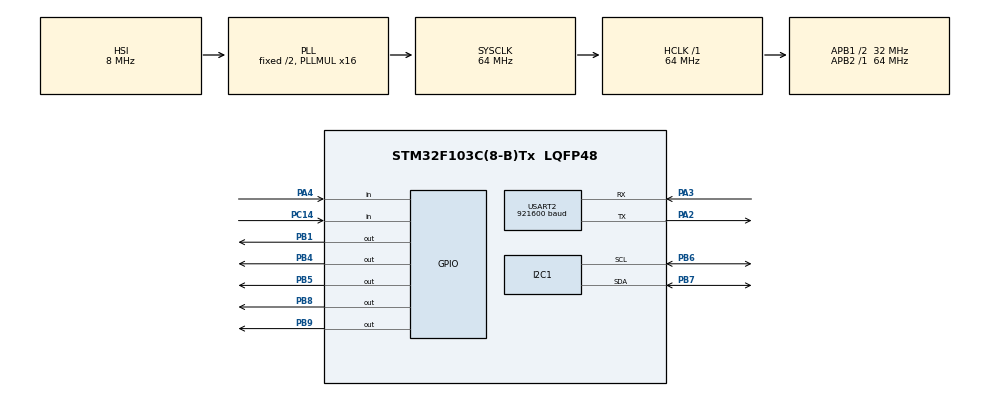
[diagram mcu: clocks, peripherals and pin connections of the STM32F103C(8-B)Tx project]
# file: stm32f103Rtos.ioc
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ADC1.Channel-0\#ChannelRegularConversion=ADC_CHANNEL_TEMPSENSOR
ADC1.NbrOfConversionFlag=1
ADC1.Rank-0\#ChannelRegularConversion=1
ADC1.SamplingTime-0\#ChannelRegularConversion=ADC_SAMPLETIME_1CYCLE_5
ADC1.master=1
Dma.Request0=USART2_RX
Dma.Request1=USART2_TX
Dma.USART2_RX.0.Direction=DMA_PERIPH_TO_MEMORY
Dma.USART2_RX.0.Instance=DMA1_Channel6
Dma.USART2_RX.0.MemDataAlignment=DMA_MDATAALIGN_BYTE
Dma.USART2_RX.0.MemInc=DMA_MINC_ENABLE
Dma.USART2_RX.0.Mode=DMA_NORMAL
Dma.USART2_RX.0.PeriphDataAlignment=DMA_PDATAALIGN_BYTE
Dma.USART2_RX.0.PeriphInc=DMA_PINC_DISABLE
Dma.USART2_RX.0.Priority=DMA_PRIORITY_LOW
Dma.USART2_TX.1.Direction=DMA_MEMORY_TO_PERIPH
Dma.USART2_TX.1.Instance=DMA1_Channel7
Dma.USART2_TX.1.MemDataAlignment=DMA_MDATAALIGN_BYTE
Dma.USART2_TX.1.MemInc=DMA_MINC_ENABLE
Dma.USART2_TX.1.Mode=DMA_NORMAL
Dma.USART2_TX.1.PeriphDataAlignment=DMA_PDATAALIGN_BYTE
Dma.USART2_TX.1.PeriphInc=DMA_PINC_DISABLE
Dma.USART2_TX.1.Priority=DMA_PRIORITY_LOW
FREERTOS.INCLUDE_uxTaskGetStackHighWaterMark=1
FREERTOS.Tasks01=defaultTask,-3,128,StartDefaultTask,Default,NULL,Dynamic,NULL,NULL
FREERTOS.configUSE_NEWLIB_REENTRANT=1
IWDG.Prescaler=IWDG_PRESCALER_64
Mcu.Family=STM32F1
Mcu.Name=STM32F103C(8-B)Tx
Mcu.Package=LQFP48
NVIC.DMA1_Channel6_IRQn=true\:6\:0\:true\:false\:true\:true\:true\:true
NVIC.DMA1_Channel7_IRQn=true\:6\:0\:true\:false\:true\:true\:true\:true
NVIC.I2C1_ER_IRQn=true\:5\:0\:false\:false\:true\:false\:true\:true
NVIC.I2C1_EV_IRQn=true\:5\:0\:false\:false\:true\:false\:true\:true
NVIC.PriorityGroup=NVIC_PRIORITYGROUP_4
NVIC.USART2_IRQn=true\:6\:0\:true\:false\:true\:true\:true\:true
PA13.Mode=Serial_Wire
PA13.Signal=SYS_JTMS-SWDIO
PA14.Mode=Serial_Wire
PA14.Signal=SYS_JTCK-SWCLK
PA2.Mode=Asynchronous
PA2.Signal=USART2_TX
PA3.Mode=Asynchronous
PA3.Signal=USART2_RX
PA4.Signal=GPIO_Input
PB1.Signal=GPIO_Output
PB4.Signal=GPIO_Output
PB5.Signal=GPIO_Output
PB6.Mode=I2C
PB6.Signal=I2C1_SCL
PB7.Mode=I2C
PB7.Signal=I2C1_SDA
PB8.Signal=GPIO_Output
PB9.Signal=GPIO_Output
PC14-OSC32_IN.Signal=GPIO_Input
ProjectManager.HeapSize=0x200
ProjectManager.StackSize=0x400
ProjectManager.TargetToolchain=STM32CubeIDE
RCC.ADCPresc=RCC_ADCPCLK2_DIV8
RCC.AHBFreq_Value=64000000
RCC.APB1CLKDivider=RCC_HCLK_DIV2
RCC.APB1Freq_Value=32000000
RCC.APB1TimFreq_Value=64000000
RCC.APB2Freq_Value=64000000
RCC.APB2TimFreq_Value=64000000
RCC.HCLKFreq_Value=64000000
RCC.PLLMUL=RCC_PLL_MUL16
RCC.SYSCLKFreq_VALUE=64000000
RCC.SYSCLKSource=RCC_SYSCLKSOURCE_PLLCLK
RCC.USBFreq_Value=64000000
USART2.BaudRate=921600
USART2.VirtualMode=VM_ASYNC
VP_ADC1_TempSens_Input.Mode=IN-TempSens
VP_CRC_VS_CRC.Mode=CRC_Activate
VP_FREERTOS_VS_CMSIS_V1.Mode=CMSIS_V1
VP_IWDG_VS_IWDG.Mode=IWDG_Activate
VP_TIM2_VS_ClockSourceINT.Mode=Internal
VP_TIM2_VS_ClockSourceITR.Mode=TriggerSource_ITR0
board=custom

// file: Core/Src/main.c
/* USER CODE BEGIN Header */
/**
  ******************************************************************************
  * @file           : main.c
  * @brief          : Main program body
  ******************************************************************************
  * @attention
  *
  * <h2><center>&copy; Copyright (c) 2021 STMicroelectronics.
  * All rights reserved.</center></h2>
  *
  * This software component is licensed by ST under Ultimate Liberty license
  * SLA0044, the "License"; You may not use this file except in compliance with
  * the License. You may obtain a copy of the License at:
  *                             www.st.com/SLA0044
  *
  ******************************************************************************
  */
/* USER CODE END Header */
#include "main.h"
#include "cmsis_os.h"

ADC_HandleTypeDef hadc1;

CRC_HandleTypeDef hcrc;

I2C_HandleTypeDef hi2c1;

IWDG_HandleTypeDef hiwdg;

TIM_HandleTypeDef htim2;

UART_HandleTypeDef huart2;
DMA_HandleTypeDef hdma_usart2_rx;
DMA_HandleTypeDef hdma_usart2_tx;

osThreadId defaultTaskHandle;

void SystemClock_Config(void);
static void MX_GPIO_Init(void);
static void MX_I2C1_Init(void);
static void MX_ADC1_Init(void);
static void MX_DMA_Init(void);
static void MX_USART2_UART_Init(void);
static void MX_TIM2_Init(void);
static void MX_IWDG_Init(void);
static void MX_CRC_Init(void);
void StartDefaultTask(void const * argument);

/* USER CODE BEGIN PFP */
extern void app_main();
/* USER CODE END PFP */

int main(void)
{

  /* MCU Configuration--------------------------------------------------------*/

  /* Reset of all peripherals, Initializes the Flash interface and the Systick. */
  HAL_Init();

  /* Configure the system clock */
  SystemClock_Config();

  /* Initialize all configured peripherals */
  MX_GPIO_Init();
  MX_I2C1_Init();
  MX_ADC1_Init();
  MX_DMA_Init();
  MX_USART2_UART_Init();
  MX_TIM2_Init();
  MX_IWDG_Init();
  MX_CRC_Init();

  /* Create the thread(s) */
  /* definition and creation of defaultTask */
  osThreadDef(defaultTask, StartDefaultTask, osPriorityIdle, 0, 128);
  defaultTaskHandle = osThreadCreate(osThread(defaultTask), NULL);

  /* USER CODE BEGIN RTOS_THREADS */
  /* add threads, ... */
  app_main();
  /* USER CODE END RTOS_THREADS */

  /* Start scheduler */
  osKernelStart();

  /* We should never get here as control is now taken by the scheduler */
  /* Infinite loop */
  while (1)
  {

  }
}

void SystemClock_Config(void)
{
  RCC_OscInitTypeDef RCC_OscInitStruct = {0};
  RCC_ClkInitTypeDef RCC_ClkInitStruct = {0};
  RCC_PeriphCLKInitTypeDef PeriphClkInit = {0};

  /** Initializes the RCC Oscillators according to the specified parameters
  * in the RCC_OscInitTypeDef structure.
  */
  RCC_OscInitStruct.OscillatorType = RCC_OSCILLATORTYPE_HSI|RCC_OSCILLATORTYPE_LSI;
  RCC_OscInitStruct.HSIState = RCC_HSI_ON;
  RCC_OscInitStruct.HSICalibrationValue = RCC_HSICALIBRATION_DEFAULT;
  RCC_OscInitStruct.LSIState = RCC_LSI_ON;
  RCC_OscInitStruct.PLL.PLLState = RCC_PLL_ON;
  RCC_OscInitStruct.PLL.PLLSource = RCC_PLLSOURCE_HSI_DIV2;
  RCC_OscInitStruct.PLL.PLLMUL = RCC_PLL_MUL16;
  if (HAL_RCC_OscConfig(&RCC_OscInitStruct) != HAL_OK)
  {
    Error_Handler();
  }
  /** Initializes the CPU, AHB and APB buses clocks
  */
  RCC_ClkInitStruct.ClockType = RCC_CLOCKTYPE_HCLK|RCC_CLOCKTYPE_SYSCLK
                              |RCC_CLOCKTYPE_PCLK1|RCC_CLOCKTYPE_PCLK2;
  RCC_ClkInitStruct.SYSCLKSource = RCC_SYSCLKSOURCE_PLLCLK;
  RCC_ClkInitStruct.AHBCLKDivider = RCC_SYSCLK_DIV1;
  RCC_ClkInitStruct.APB1CLKDivider = RCC_HCLK_DIV2;
  RCC_ClkInitStruct.APB2CLKDivider = RCC_HCLK_DIV1;

  if (HAL_RCC_ClockConfig(&RCC_ClkInitStruct, FLASH_LATENCY_2) != HAL_OK)
  {
    Error_Handler();
  }
  PeriphClkInit.PeriphClockSelection = RCC_PERIPHCLK_ADC;
  PeriphClkInit.AdcClockSelection = RCC_ADCPCLK2_DIV8;
  if (HAL_RCCEx_PeriphCLKConfig(&PeriphClkInit) != HAL_OK)
  {
    Error_Handler();
  }
}

static void MX_ADC1_Init(void)
{

  ADC_ChannelConfTypeDef sConfig = {0};

  /** Common config
  */
  hadc1.Instance = ADC1;
  hadc1.Init.ScanConvMode = ADC_SCAN_DISABLE;
  hadc1.Init.ContinuousConvMode = DISABLE;
  hadc1.Init.DiscontinuousConvMode = DISABLE;
  hadc1.Init.ExternalTrigConv = ADC_SOFTWARE_START;
  hadc1.Init.DataAlign = ADC_DATAALIGN_RIGHT;
  hadc1.Init.NbrOfConversion = 1;
  if (HAL_ADC_Init(&hadc1) != HAL_OK)
  {
    Error_Handler();
  }
  /** Configure Regular Channel
  */
  sConfig.Channel = ADC_CHANNEL_TEMPSENSOR;
  sConfig.Rank = ADC_REGULAR_RANK_1;
  sConfig.SamplingTime = ADC_SAMPLETIME_1CYCLE_5;
  if (HAL_ADC_ConfigChannel(&hadc1, &sConfig) != HAL_OK)
  {
    Error_Handler();
  }

}

static void MX_CRC_Init(void)
{

  /* USER CODE BEGIN CRC_Init 0 */
    __CRC_CLK_ENABLE();

  /* USER CODE END CRC_Init 0 */

  hcrc.Instance = CRC;
  if (HAL_CRC_Init(&hcrc) != HAL_OK)
  {
    Error_Handler();
  }

}

static void MX_I2C1_Init(void)
{

  hi2c1.Instance = I2C1;
  hi2c1.Init.ClockSpeed = 100000;
  hi2c1.Init.DutyCycle = I2C_DUTYCYCLE_2;
  hi2c1.Init.OwnAddress1 = 0;
  hi2c1.Init.AddressingMode = I2C_ADDRESSINGMODE_7BIT;
  hi2c1.Init.DualAddressMode = I2C_DUALADDRESS_DISABLE;
  hi2c1.Init.OwnAddress2 = 0;
  hi2c1.Init.GeneralCallMode = I2C_GENERALCALL_DISABLE;
  hi2c1.Init.NoStretchMode = I2C_NOSTRETCH_DISABLE;
  if (HAL_I2C_Init(&hi2c1) != HAL_OK)
  {
    Error_Handler();
  }

}

static void MX_IWDG_Init(void)
{

  hiwdg.Instance = IWDG;
  hiwdg.Init.Prescaler = IWDG_PRESCALER_64;
  hiwdg.Init.Reload = 4095;
  if (HAL_IWDG_Init(&hiwdg) != HAL_OK)
  {
    Error_Handler();
  }

}

static void MX_TIM2_Init(void)
{

  TIM_ClockConfigTypeDef sClockSourceConfig = {0};
  TIM_SlaveConfigTypeDef sSlaveConfig = {0};
  TIM_MasterConfigTypeDef sMasterConfig = {0};

  htim2.Instance = TIM2;
  htim2.Init.Prescaler = 0;
  htim2.Init.CounterMode = TIM_COUNTERMODE_UP;
  htim2.Init.Period = 65535;
  htim2.Init.ClockDivision = TIM_CLOCKDIVISION_DIV1;
  htim2.Init.AutoReloadPreload = TIM_AUTORELOAD_PRELOAD_DISABLE;
  if (HAL_TIM_Base_Init(&htim2) != HAL_OK)
  {
    Error_Handler();
  }
  sClockSourceConfig.ClockSource = TIM_CLOCKSOURCE_INTERNAL;
  if (HAL_TIM_ConfigClockSource(&htim2, &sClockSourceConfig) != HAL_OK)
  {
    Error_Handler();
  }
  sSlaveConfig.SlaveMode = TIM_SLAVEMODE_DISABLE;
  sSlaveConfig.InputTrigger = TIM_TS_ITR0;
  if (HAL_TIM_SlaveConfigSynchro(&htim2, &sSlaveConfig) != HAL_OK)
  {
    Error_Handler();
  }
  sMasterConfig.MasterOutputTrigger = TIM_TRGO_RESET;
  sMasterConfig.MasterSlaveMode = TIM_MASTERSLAVEMODE_DISABLE;
  if (HAL_TIMEx_MasterConfigSynchronization(&htim2, &sMasterConfig) != HAL_OK)
  {
    Error_Handler();
  }

}

static void MX_USART2_UART_Init(void)
{

  huart2.Instance = USART2;
  huart2.Init.BaudRate = 921600;
  huart2.Init.WordLength = UART_WORDLENGTH_8B;
  huart2.Init.StopBits = UART_STOPBITS_1;
  huart2.Init.Parity = UART_PARITY_NONE;
  huart2.Init.Mode = UART_MODE_TX_RX;
  huart2.Init.HwFlowCtl = UART_HWCONTROL_NONE;
  huart2.Init.OverSampling = UART_OVERSAMPLING_16;
  if (HAL_UART_Init(&huart2) != HAL_OK)
  {
    Error_Handler();
  }

}

static void MX_DMA_Init(void)
{

  /* DMA controller clock enable */
  __HAL_RCC_DMA1_CLK_ENABLE();

  /* DMA interrupt init */
  /* DMA1_Channel6_IRQn interrupt configuration */
  HAL_NVIC_SetPriority(DMA1_Channel6_IRQn, 6, 0);
  HAL_NVIC_EnableIRQ(DMA1_Channel6_IRQn);
  /* DMA1_Channel7_IRQn interrupt configuration */
  HAL_NVIC_SetPriority(DMA1_Channel7_IRQn, 6, 0);
  HAL_NVIC_EnableIRQ(DMA1_Channel7_IRQn);

}

static void MX_GPIO_Init(void)
{
  GPIO_InitTypeDef GPIO_InitStruct = {0};

  /* GPIO Ports Clock Enable */
  __HAL_RCC_GPIOC_CLK_ENABLE();
  __HAL_RCC_GPIOA_CLK_ENABLE();
  __HAL_RCC_GPIOB_CLK_ENABLE();

  /*Configure GPIO pin Output Level */
  HAL_GPIO_WritePin(GPIOB, GPIO_PIN_1|GPIO_PIN_4|GPIO_PIN_5|GPIO_PIN_8
                          |GPIO_PIN_9, GPIO_PIN_RESET);

  /*Configure GPIO pin : PC14 */
  GPIO_InitStruct.Pin = GPIO_PIN_14;
  GPIO_InitStruct.Mode = GPIO_MODE_INPUT;
  GPIO_InitStruct.Pull = GPIO_NOPULL;
  HAL_GPIO_Init(GPIOC, &GPIO_InitStruct);

  /*Configure GPIO pin : PA4 */
  GPIO_InitStruct.Pin = GPIO_PIN_4;
  GPIO_InitStruct.Mode = GPIO_MODE_INPUT;
  GPIO_InitStruct.Pull = GPIO_NOPULL;
  HAL_GPIO_Init(GPIOA, &GPIO_InitStruct);

  /*Configure GPIO pins : PB1 PB4 PB5 PB8
                           PB9 */
  GPIO_InitStruct.Pin = GPIO_PIN_1|GPIO_PIN_4|GPIO_PIN_5|GPIO_PIN_8
                          |GPIO_PIN_9;
  GPIO_InitStruct.Mode = GPIO_MODE_OUTPUT_PP;
  GPIO_InitStruct.Pull = GPIO_NOPULL;
  GPIO_InitStruct.Speed = GPIO_SPEED_FREQ_LOW;
  HAL_GPIO_Init(GPIOB, &GPIO_InitStruct);

}

void StartDefaultTask(void const * argument)
{
  /* USER CODE BEGIN 5 */
  /* Infinite loop */
  for(;;)
  {
    osDelay(1);
    HAL_IWDG_Refresh(&hiwdg);
  }
  /* USER CODE END 5 */
}

void Error_Handler(void)
{
  __disable_irq();
  while (1)
  {
  }
}

/************************ (C) COPYRIGHT STMicroelectronics *****END OF FILE****/
